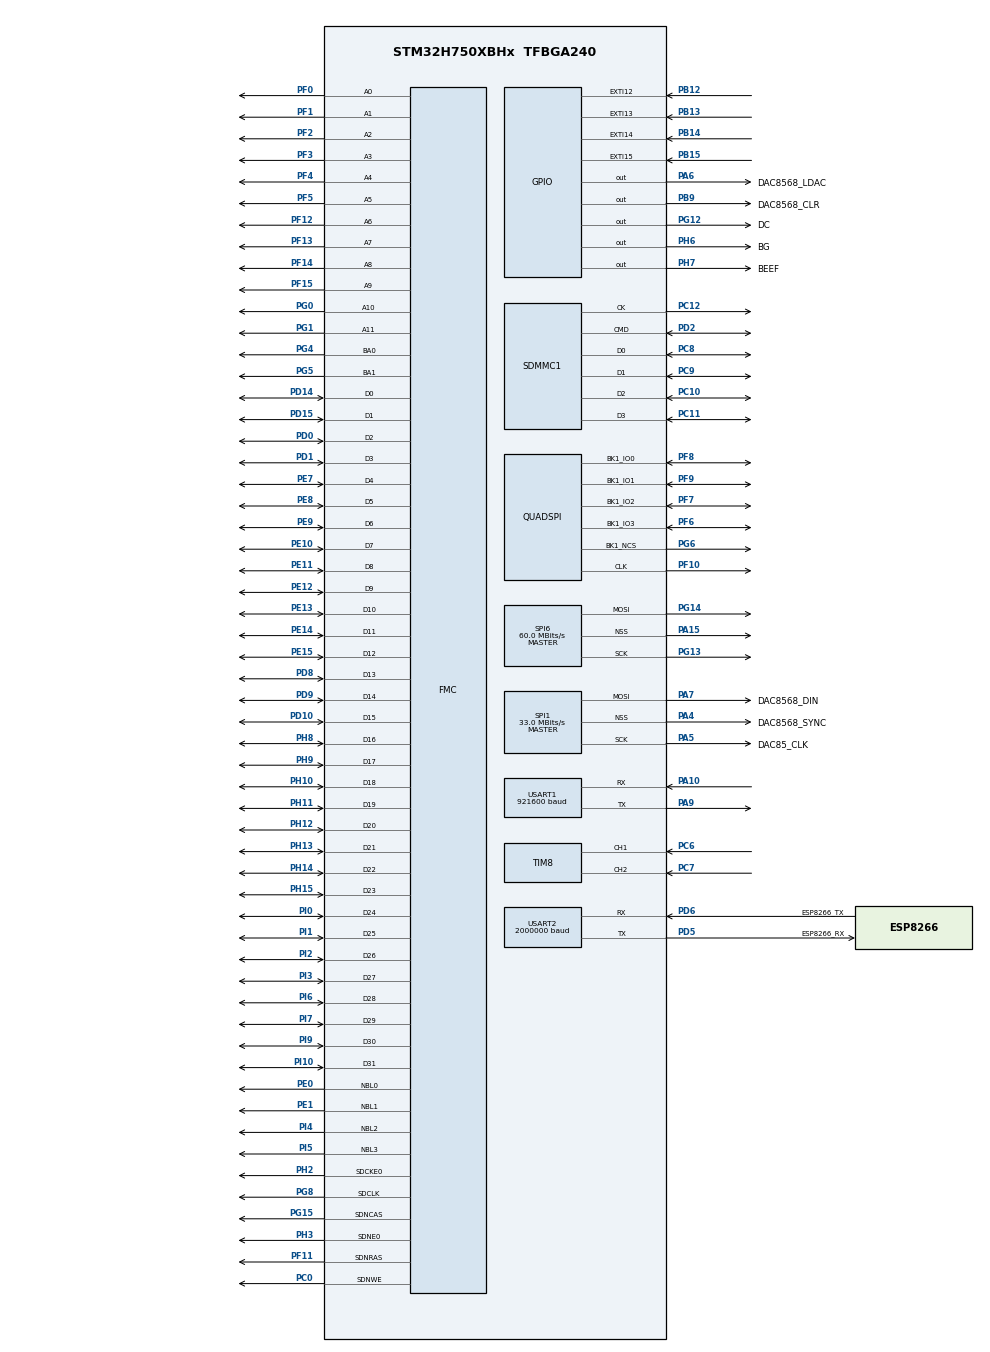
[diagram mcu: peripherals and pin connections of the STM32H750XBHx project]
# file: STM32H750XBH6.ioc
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CORTEX_M7.AccessPermission-Cortex_Memory_Protection_Unit_Region0_Settings=MPU_REGION_FULL_ACCESS
CORTEX_M7.AccessPermission-Cortex_Memory_Protection_Unit_Region1_Settings=MPU_REGION_FULL_ACCESS
CORTEX_M7.BaseAddress-Cortex_Memory_Protection_Unit_Region0_Settings=0xC0000000
CORTEX_M7.BaseAddress-Cortex_Memory_Protection_Unit_Region1_Settings=0x24000000
CORTEX_M7.CPU_DCache=Enabled
CORTEX_M7.CPU_ICache=Enabled
CORTEX_M7.Enable-Cortex_Memory_Protection_Unit_Region0_Settings=MPU_REGION_ENABLE
CORTEX_M7.Enable-Cortex_Memory_Protection_Unit_Region1_Settings=MPU_REGION_ENABLE
CORTEX_M7.IsBufferable-Cortex_Memory_Protection_Unit_Region0_Settings=MPU_ACCESS_NOT_BUFFERABLE
CORTEX_M7.IsBufferable-Cortex_Memory_Protection_Unit_Region1_Settings=MPU_ACCESS_BUFFERABLE
CORTEX_M7.IsCacheable-Cortex_Memory_Protection_Unit_Region0_Settings=MPU_ACCESS_CACHEABLE
CORTEX_M7.IsCacheable-Cortex_Memory_Protection_Unit_Region1_Settings=MPU_ACCESS_CACHEABLE
CORTEX_M7.IsShareable-Cortex_Memory_Protection_Unit_Region1_Settings=MPU_ACCESS_SHAREABLE
CORTEX_M7.MPU_Control=MPU_PRIVILEGED_DEFAULT
CORTEX_M7.Size-Cortex_Memory_Protection_Unit_Region0_Settings=MPU_REGION_SIZE_16MB
CORTEX_M7.Size-Cortex_Memory_Protection_Unit_Region1_Settings=MPU_REGION_SIZE_512KB
CORTEX_M7.TypeExtField-Cortex_Memory_Protection_Unit_Region1_Settings=MPU_TEX_LEVEL1
DMA2D.ColorMode=DMA2D_OUTPUT_RGB565
Dma.Request0=USART1_RX
Dma.Request1=USART1_TX
Dma.Request2=USART2_RX
Dma.Request3=USART2_TX
Dma.Request4=SPI1_TX
Dma.SPI1_TX.4.Direction=DMA_MEMORY_TO_PERIPH
Dma.SPI1_TX.4.EventEnable=DISABLE
Dma.SPI1_TX.4.FIFOMode=DMA_FIFOMODE_DISABLE
Dma.SPI1_TX.4.Instance=DMA1_Stream4
Dma.SPI1_TX.4.MemDataAlignment=DMA_MDATAALIGN_WORD
Dma.SPI1_TX.4.MemInc=DMA_MINC_ENABLE
Dma.SPI1_TX.4.Mode=DMA_CIRCULAR
Dma.SPI1_TX.4.PeriphDataAlignment=DMA_PDATAALIGN_WORD
Dma.SPI1_TX.4.PeriphInc=DMA_PINC_DISABLE
Dma.SPI1_TX.4.Polarity=HAL_DMAMUX_REQ_GEN_RISING
Dma.SPI1_TX.4.Priority=DMA_PRIORITY_HIGH
Dma.SPI1_TX.4.RequestNumber=1
Dma.SPI1_TX.4.SignalID=NONE
Dma.SPI1_TX.4.SyncEnable=DISABLE
Dma.SPI1_TX.4.SyncPolarity=HAL_DMAMUX_SYNC_NO_EVENT
Dma.SPI1_TX.4.SyncRequestNumber=1
Dma.SPI1_TX.4.SyncSignalID=NONE
Dma.USART1_RX.0.Direction=DMA_PERIPH_TO_MEMORY
Dma.USART1_RX.0.EventEnable=DISABLE
Dma.USART1_RX.0.FIFOMode=DMA_FIFOMODE_DISABLE
Dma.USART1_RX.0.Instance=DMA1_Stream0
Dma.USART1_RX.0.MemDataAlignment=DMA_MDATAALIGN_BYTE
Dma.USART1_RX.0.MemInc=DMA_MINC_ENABLE
Dma.USART1_RX.0.Mode=DMA_NORMAL
Dma.USART1_RX.0.PeriphDataAlignment=DMA_PDATAALIGN_BYTE
Dma.USART1_RX.0.PeriphInc=DMA_PINC_DISABLE
Dma.USART1_RX.0.Polarity=HAL_DMAMUX_REQ_GEN_RISING
Dma.USART1_RX.0.Priority=DMA_PRIORITY_VERY_HIGH
Dma.USART1_RX.0.RequestNumber=1
Dma.USART1_RX.0.SignalID=NONE
Dma.USART1_RX.0.SyncEnable=DISABLE
Dma.USART1_RX.0.SyncPolarity=HAL_DMAMUX_SYNC_NO_EVENT
Dma.USART1_RX.0.SyncRequestNumber=1
Dma.USART1_RX.0.SyncSignalID=NONE
Dma.USART1_TX.1.Direction=DMA_MEMORY_TO_PERIPH
Dma.USART1_TX.1.EventEnable=DISABLE
Dma.USART1_TX.1.FIFOMode=DMA_FIFOMODE_DISABLE
Dma.USART1_TX.1.Instance=DMA1_Stream1
Dma.USART1_TX.1.MemDataAlignment=DMA_MDATAALIGN_BYTE
Dma.USART1_TX.1.MemInc=DMA_MINC_ENABLE
Dma.USART1_TX.1.Mode=DMA_NORMAL
Dma.USART1_TX.1.PeriphDataAlignment=DMA_PDATAALIGN_BYTE
Dma.USART1_TX.1.PeriphInc=DMA_PINC_DISABLE
Dma.USART1_TX.1.Polarity=HAL_DMAMUX_REQ_GEN_RISING
Dma.USART1_TX.1.Priority=DMA_PRIORITY_VERY_HIGH
Dma.USART1_TX.1.RequestNumber=1
Dma.USART1_TX.1.SignalID=NONE
Dma.USART1_TX.1.SyncEnable=DISABLE
Dma.USART1_TX.1.SyncPolarity=HAL_DMAMUX_SYNC_NO_EVENT
Dma.USART1_TX.1.SyncRequestNumber=1
Dma.USART1_TX.1.SyncSignalID=NONE
Dma.USART2_RX.2.Direction=DMA_PERIPH_TO_MEMORY
Dma.USART2_RX.2.EventEnable=DISABLE
Dma.USART2_RX.2.FIFOMode=DMA_FIFOMODE_DISABLE
Dma.USART2_RX.2.Instance=DMA1_Stream2
Dma.USART2_RX.2.MemDataAlignment=DMA_MDATAALIGN_BYTE
Dma.USART2_RX.2.MemInc=DMA_MINC_ENABLE
Dma.USART2_RX.2.Mode=DMA_CIRCULAR
Dma.USART2_RX.2.PeriphDataAlignment=DMA_PDATAALIGN_BYTE
Dma.USART2_RX.2.PeriphInc=DMA_PINC_DISABLE
Dma.USART2_RX.2.Polarity=HAL_DMAMUX_REQ_GEN_RISING
Dma.USART2_RX.2.Priority=DMA_PRIORITY_VERY_HIGH
Dma.USART2_RX.2.RequestNumber=1
Dma.USART2_RX.2.SignalID=NONE
Dma.USART2_RX.2.SyncEnable=DISABLE
Dma.USART2_RX.2.SyncPolarity=HAL_DMAMUX_SYNC_NO_EVENT
Dma.USART2_RX.2.SyncRequestNumber=1
Dma.USART2_RX.2.SyncSignalID=NONE
Dma.USART2_TX.3.Direction=DMA_MEMORY_TO_PERIPH
Dma.USART2_TX.3.EventEnable=DISABLE
Dma.USART2_TX.3.FIFOMode=DMA_FIFOMODE_DISABLE
Dma.USART2_TX.3.Instance=DMA1_Stream3
Dma.USART2_TX.3.MemDataAlignment=DMA_MDATAALIGN_BYTE
Dma.USART2_TX.3.MemInc=DMA_MINC_ENABLE
Dma.USART2_TX.3.Mode=DMA_NORMAL
Dma.USART2_TX.3.PeriphDataAlignment=DMA_PDATAALIGN_BYTE
Dma.USART2_TX.3.PeriphInc=DMA_PINC_DISABLE
Dma.USART2_TX.3.Polarity=HAL_DMAMUX_REQ_GEN_RISING
Dma.USART2_TX.3.Priority=DMA_PRIORITY_VERY_HIGH
Dma.USART2_TX.3.RequestNumber=1
Dma.USART2_TX.3.SignalID=NONE
Dma.USART2_TX.3.SyncEnable=DISABLE
Dma.USART2_TX.3.SyncPolarity=HAL_DMAMUX_SYNC_NO_EVENT
Dma.USART2_TX.3.SyncRequestNumber=1
Dma.USART2_TX.3.SyncSignalID=NONE
FATFS._CODE_PAGE=437
FATFS._FS_LOCK=16
FATFS._USE_LFN=3
FATFS._VOLUMES=1
FMC.CASLatency1=FMC_SDRAM_CAS_LATENCY_3
FMC.ColumnBitsNumber1=FMC_SDRAM_COLUMN_BITS_NUM_8
FMC.ExitSelfRefreshDelay1=7
FMC.LoadToActiveDelay1=2
FMC.RCDDelay1=2
FMC.RPDelay1=2
FMC.RPDelay2=2
FMC.ReadBurst1=FMC_SDRAM_RBURST_ENABLE
FMC.ReadBurst2=FMC_SDRAM_RBURST_ENABLE
FMC.RowCycleDelay1=7
FMC.RowCycleDelay2=7
FMC.SDClockPeriod1=FMC_SDRAM_CLOCK_PERIOD_2
FMC.SDClockPeriod2=FMC_SDRAM_CLOCK_PERIOD_2
FMC.SelfRefreshTime1=4
FMC.WriteRecoveryTime1=3
FREERTOS.Tasks01=LVGL940,24,2048,LVGL_Task,Default,NULL,Dynamic,NULL,NULL;LED,8,128,LED_Task,Default,NULL,Dynamic,NULL,NULL;Main,8,8192,Main_Task,Default,NULL,Dynamic,NULL,NULL;ESP8266,32,5128,ESP8266_Task,Default,NULL,Dynamic,NULL,NULL
FREERTOS.configTOTAL_HEAP_SIZE=102400
FREERTOS.configUSE_TICK_HOOK=1
Mcu.Family=STM32H7
Mcu.Name=STM32H750XBHx
Mcu.Package=TFBGA240
Mdma.MDMA_Channel0.Request0=SDMMC1_END_DATA
Mdma.MDMA_Channel0.RequestsNb=1
Mdma.MDMA_Channel0.SDMMC1_END_DATA.0.BlockCount=0
Mdma.MDMA_Channel0.SDMMC1_END_DATA.0.BlockDataLength=0
Mdma.MDMA_Channel0.SDMMC1_END_DATA.0.BufferTransferLength=1
Mdma.MDMA_Channel0.SDMMC1_END_DATA.0.CircularMode=MDMA_LINEAR_LIST
Mdma.MDMA_Channel0.SDMMC1_END_DATA.0.DataAlignment=MDMA_DATAALIGN_PACKENABLE
Mdma.MDMA_Channel0.SDMMC1_END_DATA.0.DestBlockAddressOffset=0
Mdma.MDMA_Channel0.SDMMC1_END_DATA.0.DestBurst=MDMA_DEST_BURST_SINGLE
Mdma.MDMA_Channel0.SDMMC1_END_DATA.0.DestDataSize=MDMA_DEST_DATASIZE_BYTE
Mdma.MDMA_Channel0.SDMMC1_END_DATA.0.DestinationInc=MDMA_DEST_INC_BYTE
Mdma.MDMA_Channel0.SDMMC1_END_DATA.0.DstAddress=0
Mdma.MDMA_Channel0.SDMMC1_END_DATA.0.Endianness=MDMA_LITTLE_ENDIANNESS_PRESERVE
Mdma.MDMA_Channel0.SDMMC1_END_DATA.0.Instance=MDMA_Channel0
Mdma.MDMA_Channel0.SDMMC1_END_DATA.0.MaskAddress=0
Mdma.MDMA_Channel0.SDMMC1_END_DATA.0.MaskData=0
Mdma.MDMA_Channel0.SDMMC1_END_DATA.0.Priority=MDMA_PRIORITY_LOW
Mdma.MDMA_Channel0.SDMMC1_END_DATA.0.Rank=First
Mdma.MDMA_Channel0.SDMMC1_END_DATA.0.SourceBlockAddressOffset=0
Mdma.MDMA_Channel0.SDMMC1_END_DATA.0.SourceBurst=MDMA_SOURCE_BURST_SINGLE
Mdma.MDMA_Channel0.SDMMC1_END_DATA.0.SourceDataSize=MDMA_SRC_DATASIZE_BYTE
Mdma.MDMA_Channel0.SDMMC1_END_DATA.0.SourceInc=MDMA_SRC_INC_BYTE
Mdma.MDMA_Channel0.SDMMC1_END_DATA.0.SrcAddress=0
Mdma.MDMA_Channel0.SDMMC1_END_DATA.0.TransferTriggerMode=MDMA_BUFFER_TRANSFER
Mdma.MDMA_Channel1.QUADSPI_FIFO_TH.0.BlockCount=0
Mdma.MDMA_Channel1.QUADSPI_FIFO_TH.0.BlockDataLength=0
Mdma.MDMA_Channel1.QUADSPI_FIFO_TH.0.BufferTransferLength=128
Mdma.MDMA_Channel1.QUADSPI_FIFO_TH.0.CircularMode=MDMA_LINEAR_LIST
Mdma.MDMA_Channel1.QUADSPI_FIFO_TH.0.DataAlignment=MDMA_DATAALIGN_PACKENABLE
Mdma.MDMA_Channel1.QUADSPI_FIFO_TH.0.DestBlockAddressOffset=0
Mdma.MDMA_Channel1.QUADSPI_FIFO_TH.0.DestBurst=MDMA_DEST_BURST_SINGLE
Mdma.MDMA_Channel1.QUADSPI_FIFO_TH.0.DestDataSize=MDMA_DEST_DATASIZE_WORD
Mdma.MDMA_Channel1.QUADSPI_FIFO_TH.0.DestinationInc=MDMA_DEST_INC_DISABLE
Mdma.MDMA_Channel1.QUADSPI_FIFO_TH.0.DstAddress=0
Mdma.MDMA_Channel1.QUADSPI_FIFO_TH.0.Endianness=MDMA_LITTLE_ENDIANNESS_PRESERVE
Mdma.MDMA_Channel1.QUADSPI_FIFO_TH.0.Instance=MDMA_Channel1
Mdma.MDMA_Channel1.QUADSPI_FIFO_TH.0.MaskAddress=0
Mdma.MDMA_Channel1.QUADSPI_FIFO_TH.0.MaskData=0
Mdma.MDMA_Channel1.QUADSPI_FIFO_TH.0.Priority=MDMA_PRIORITY_VERY_HIGH
Mdma.MDMA_Channel1.QUADSPI_FIFO_TH.0.Rank=First
Mdma.MDMA_Channel1.QUADSPI_FIFO_TH.0.SourceBlockAddressOffset=0
Mdma.MDMA_Channel1.QUADSPI_FIFO_TH.0.SourceBurst=MDMA_SOURCE_BURST_SINGLE
Mdma.MDMA_Channel1.QUADSPI_FIFO_TH.0.SourceDataSize=MDMA_SRC_DATASIZE_WORD
Mdma.MDMA_Channel1.QUADSPI_FIFO_TH.0.SourceInc=MDMA_SRC_INC_WORD
Mdma.MDMA_Channel1.QUADSPI_FIFO_TH.0.SrcAddress=0
Mdma.MDMA_Channel1.QUADSPI_FIFO_TH.0.TransferTriggerMode=MDMA_BUFFER_TRANSFER
Mdma.MDMA_Channel1.Request0=QUADSPI_FIFO_TH
Mdma.MDMA_Channel1.RequestsNb=1
Mdma.RequestSet0=MDMA_Channel0
Mdma.RequestSet1=MDMA_Channel1
Mdma.RequestSetsNb=2
NVIC.DMA1_Stream0_IRQn=true\:5\:0\:false\:false\:true\:true\:false\:true\:true
NVIC.DMA1_Stream1_IRQn=true\:5\:0\:false\:false\:true\:true\:false\:true\:true
NVIC.DMA1_Stream2_IRQn=true\:5\:0\:false\:false\:true\:true\:false\:true\:true
NVIC.DMA1_Stream3_IRQn=true\:5\:0\:false\:false\:true\:true\:false\:true\:true
NVIC.DMA1_Stream4_IRQn=true\:5\:0\:false\:false\:true\:true\:false\:true\:true
NVIC.EXTI15_10_IRQn=true\:7\:0\:true\:false\:true\:true\:true\:true\:true
NVIC.MDMA_IRQn=true\:6\:0\:true\:false\:true\:true\:false\:true\:true
NVIC.PriorityGroup=NVIC_PRIORITYGROUP_4
NVIC.QUADSPI_IRQn=true\:5\:0\:false\:false\:true\:true\:true\:true\:true
NVIC.SDMMC1_IRQn=true\:6\:0\:true\:false\:true\:true\:true\:true\:true
NVIC.SPI1_IRQn=true\:5\:0\:false\:false\:true\:true\:false\:true\:true
NVIC.TIM17_IRQn=true\:15\:0\:false\:false\:true\:false\:false\:true\:true
NVIC.TIM3_IRQn=true\:5\:0\:false\:false\:true\:true\:true\:true\:true
NVIC.TIM8_BRK_TIM12_IRQn=true\:5\:0\:false\:false\:true\:true\:true\:true\:true
NVIC.TimeBase=TIM17_IRQn
NVIC.TimeBaseIP=TIM17
NVIC.USART1_IRQn=true\:5\:0\:false\:false\:true\:true\:true\:true\:true
NVIC.USART2_IRQn=true\:5\:0\:false\:false\:true\:true\:true\:true\:true
PA10.GPIO_Speed=GPIO_SPEED_FREQ_VERY_HIGH
PA10.Mode=Asynchronous
PA10.PinAttribute=Free
PA10.Signal=USART1_RX
PA13\ (JTMS/SWDIO).Mode=Serial_Wire
PA13\ (JTMS/SWDIO).Signal=DEBUG_JTMS-SWDIO
PA14\ (JTCK/SWCLK).Mode=Serial_Wire
PA14\ (JTCK/SWCLK).PinAttribute=Free
PA14\ (JTCK/SWCLK).Signal=DEBUG_JTCK-SWCLK
PA15\ (JTDI).GPIO_Speed=GPIO_SPEED_FREQ_VERY_HIGH
PA15\ (JTDI).Mode=NSS_Signal_Hard_Output
PA15\ (JTDI).Signal=SPI6_NSS
PA4.GPIO_Label=DAC8568_SYNC
PA4.GPIO_Speed=GPIO_SPEED_FREQ_VERY_HIGH
PA4.Mode=NSS_Signal_Hard_Output
PA4.Signal=SPI1_NSS
PA5.GPIO_Label=DAC85_CLK
PA5.GPIO_Speed=GPIO_SPEED_FREQ_LOW
PA5.Mode=TX_Only_Simplex_Unidirect_Master
PA5.PinAttribute=Free
PA5.Signal=SPI1_SCK
PA6.GPIO_Label=DAC8568_LDAC
PA6.GPIO_Speed=GPIO_SPEED_FREQ_VERY_HIGH
PA6.PinAttribute=Free
PA6.PinState=GPIO_PIN_SET
PA6.Signal=GPIO_Output
PA7.GPIO_Label=DAC8568_DIN
PA7.GPIO_Speed=GPIO_SPEED_FREQ_LOW
PA7.Mode=TX_Only_Simplex_Unidirect_Master
PA7.PinAttribute=Free
PA7.Signal=SPI1_MOSI
PA9.GPIO_Speed=GPIO_SPEED_FREQ_VERY_HIGH
PA9.Mode=Asynchronous
PA9.PinAttribute=Free
PA9.Signal=USART1_TX
PB12.GPIO_ModeDefaultEXTI=GPIO_MODE_IT_FALLING
PB12.GPIO_PuPd=GPIO_PULLUP
PB12.PinAttribute=Free
PB12.Signal=GPXTI12
PB13.GPIO_ModeDefaultEXTI=GPIO_MODE_IT_FALLING
PB13.GPIO_PuPd=GPIO_PULLUP
PB13.Signal=GPXTI13
PB14.GPIO_ModeDefaultEXTI=GPIO_MODE_IT_FALLING
PB14.GPIO_PuPd=GPIO_PULLUP
PB14.Signal=GPXTI14
PB15.GPIO_ModeDefaultEXTI=GPIO_MODE_IT_FALLING
PB15.GPIO_PuPd=GPIO_PULLUP
PB15.PinAttribute=Free
PB15.Signal=GPXTI15
PB9.GPIO_Label=DAC8568_CLR
PB9.GPIO_Speed=GPIO_SPEED_FREQ_LOW
PB9.PinState=GPIO_PIN_SET
PB9.Signal=GPIO_Output
PC0.Signal=FMC_SDNWE
PC10.GPIO_PuPd=GPIO_NOPULL
PC10.Mode=SD_4_bits_Wide_bus
PC10.Signal=SDMMC1_D2
PC11.GPIO_PuPd=GPIO_NOPULL
PC11.Mode=SD_4_bits_Wide_bus
PC11.PinAttribute=Free
PC11.Signal=SDMMC1_D3
PC12.GPIO_PuPd=GPIO_NOPULL
PC12.Mode=SD_4_bits_Wide_bus
PC12.Signal=SDMMC1_CK
PC14-OSC32_IN\ (OSC32_IN).Mode=LSE-External-Oscillator
PC14-OSC32_IN\ (OSC32_IN).Signal=RCC_OSC32_IN
PC15-OSC32_OUT\ (OSC32_OUT).Mode=LSE-External-Oscillator
PC15-OSC32_OUT\ (OSC32_OUT).Signal=RCC_OSC32_OUT
PC6.Signal=S_TIM8_CH1
PC7.Signal=S_TIM8_CH2
PC8.GPIO_PuPd=GPIO_NOPULL
PC8.Mode=SD_4_bits_Wide_bus
PC8.PinAttribute=Free
PC8.Signal=SDMMC1_D0
PC9.GPIO_PuPd=GPIO_NOPULL
PC9.Mode=SD_4_bits_Wide_bus
PC9.PinAttribute=Free
PC9.Signal=SDMMC1_D1
PD0.PinAttribute=Free
PD0.Signal=FMC_D2_DA2
PD1.PinAttribute=Free
PD1.Signal=FMC_D3_DA3
PD10.Signal=FMC_D15_DA15
PD14.Signal=FMC_D0_DA0
PD15.Signal=FMC_D1_DA1
PD2.GPIO_PuPd=GPIO_NOPULL
PD2.Mode=SD_4_bits_Wide_bus
PD2.PinAttribute=Free
PD2.Signal=SDMMC1_CMD
PD5.GPIO_Label=ESP8266_RX
PD5.GPIO_Speed=GPIO_SPEED_FREQ_VERY_HIGH
PD5.Mode=Asynchronous
PD5.Signal=USART2_TX
PD6.GPIO_Label=ESP8266_TX
PD6.GPIO_Speed=GPIO_SPEED_FREQ_VERY_HIGH
PD6.Mode=Asynchronous
PD6.PinAttribute=Free
PD6.Signal=USART2_RX
PD8.Signal=FMC_D13_DA13
PD9.Signal=FMC_D14_DA14
PE0.Signal=FMC_NBL0
PE1.Signal=FMC_NBL1
PE10.Signal=FMC_D7_DA7
PE11.Signal=FMC_D8_DA8
PE12.PinAttribute=Free
PE12.Signal=FMC_D9_DA9
PE13.PinAttribute=Free
PE13.Signal=FMC_D10_DA10
PE14.Signal=FMC_D11_DA11
PE15.PinAttribute=Free
PE15.Signal=FMC_D12_DA12
PE7.Signal=FMC_D4_DA4
PE8.PinAttribute=Free
PE8.Signal=FMC_D5_DA5
PE9.Signal=FMC_D6_DA6
PF0.Signal=FMC_A0
PF1.Signal=FMC_A1
PF10.GPIO_Speed=GPIO_SPEED_FREQ_VERY_HIGH
PF10.Mode=Single Bank 1
PF10.Signal=QUADSPI_CLK
PF11.PinAttribute=Free
PF11.Signal=FMC_SDNRAS
PF12.PinAttribute=Free
PF12.Signal=FMC_A6
PF13.Signal=FMC_A7
PF14.Signal=FMC_A8
PF15.PinAttribute=Free
PF15.Signal=FMC_A9
PF2.Signal=FMC_A2
PF3.Signal=FMC_A3
PF4.Signal=FMC_A4
PF5.Signal=FMC_A5
PF6.GPIO_Speed=GPIO_SPEED_FREQ_VERY_HIGH
PF6.Mode=Single Bank 1
PF6.Signal=QUADSPI_BK1_IO3
PF7.GPIO_Speed=GPIO_SPEED_FREQ_VERY_HIGH
PF7.Mode=Single Bank 1
PF7.Signal=QUADSPI_BK1_IO2
PF8.GPIO_Speed=GPIO_SPEED_FREQ_VERY_HIGH
PF8.Mode=Single Bank 1
PF8.Signal=QUADSPI_BK1_IO0
PF9.GPIO_Speed=GPIO_SPEED_FREQ_VERY_HIGH
PF9.Mode=Single Bank 1
PF9.Signal=QUADSPI_BK1_IO1
PG0.PinAttribute=Free
PG0.Signal=FMC_A10
PG1.Signal=FMC_A11
PG12.GPIO_Label=DC
PG12.GPIO_Speed=GPIO_SPEED_FREQ_VERY_HIGH
PG12.Signal=GPIO_Output
PG13.GPIO_Speed=GPIO_SPEED_FREQ_VERY_HIGH
PG13.Mode=TX_Only_Simplex_Unidirect_Master
PG13.PinAttribute=Free
PG13.Signal=SPI6_SCK
PG14.GPIO_Speed=GPIO_SPEED_FREQ_VERY_HIGH
PG14.Mode=TX_Only_Simplex_Unidirect_Master
PG14.Signal=SPI6_MOSI
PG15.Signal=FMC_SDNCAS
PG4.Signal=FMC_A14_BA0
PG5.Signal=FMC_A15_BA1
PG6.GPIO_Speed=GPIO_SPEED_FREQ_VERY_HIGH
PG6.Mode=Single Bank 1
PG6.Signal=QUADSPI_BK1_NCS
PG8.Signal=FMC_SDCLK
PH0-OSC_IN\ (PH0).Mode=HSE-External-Oscillator
PH0-OSC_IN\ (PH0).Signal=RCC_OSC_IN
PH1-OSC_OUT\ (PH1).Mode=HSE-External-Oscillator
PH1-OSC_OUT\ (PH1).Signal=RCC_OSC_OUT
PH10.Signal=FMC_D18
PH11.Signal=FMC_D19
PH12.PinAttribute=Free
PH12.Signal=FMC_D20
PH13.PinAttribute=Free
PH13.Signal=FMC_D21
PH14.Signal=FMC_D22
PH15.Signal=FMC_D23
PH2.Mode=SdramChipSelect1_1
PH2.Signal=FMC_SDCKE0
PH3.Mode=SdramChipSelect1_1
PH3.Signal=FMC_SDNE0
PH6.GPIO_Label=BG
PH6.GPIO_Speed=GPIO_SPEED_FREQ_VERY_HIGH
PH6.PinAttribute=Free
PH6.PinState=GPIO_PIN_SET
PH6.Signal=GPIO_Output
PH7.GPIO_Label=BEEF
PH7.GPIO_Speed=GPIO_SPEED_FREQ_VERY_HIGH
PH7.PinState=GPIO_PIN_SET
PH7.Signal=GPIO_Output
PH8.PinAttribute=Free
PH8.Signal=FMC_D16
PH9.PinAttribute=Free
PH9.Signal=FMC_D17
PI0.Signal=FMC_D24
PI1.Signal=FMC_D25
PI10.Signal=FMC_D31
PI2.Signal=FMC_D26
PI3.Signal=FMC_D27
PI4.Signal=FMC_NBL2
PI5.PinAttribute=Free
PI5.Signal=FMC_NBL3
PI6.Signal=FMC_D28
PI7.Signal=FMC_D29
PI9.PinAttribute=Free
PI9.Signal=FMC_D30
ProjectManager.HeapSize=0x2000
ProjectManager.StackSize=0x2000
ProjectManager.TargetToolchain=MDK-ARM V5.32
QUADSPI.ClockMode=QSPI_CLOCK_MODE_3
QUADSPI.ClockPrescaler=1
QUADSPI.FifoThreshold=32
QUADSPI.FlashSize=24
QUADSPI.SampleShifting=QSPI_SAMPLE_SHIFTING_HALFCYCLE
RCC.ADCFreq_Value=132000000
RCC.APB1Freq_Value=120000000
RCC.APB2Freq_Value=120000000
RCC.APB3Freq_Value=120000000
RCC.APB4Freq_Value=120000000
RCC.CortexFreq_Value=480000000
RCC.D1PPRE=RCC_APB3_DIV2
RCC.D2PPRE1=RCC_APB1_DIV2
RCC.D2PPRE2=RCC_APB2_DIV2
RCC.D3PPRE=RCC_APB4_DIV2
RCC.DIVM1=4
RCC.DIVM3=8
RCC.DIVN1=60
RCC.DIVN2=132
RCC.DIVN3=50
RCC.DIVQ1=4
RCC.DIVQ3=8
RCC.DIVR3=8
RCC.HCLKFreq_Value=240000000
RCC.HPRE=RCC_HCLK_DIV2
RCC.PLL2FRACN=0
RCC.PLL3FRACN=0
RCC.PLLFRACN=0
RCC.RTCClockSelection=RCC_RTCCLKSOURCE_LSE
RCC.SPI123CLockSelection=RCC_SPI123CLKSOURCE_PLL2
RCC.SYSCLKFreq_VALUE=480000000
RCC.SYSCLKSource=RCC_SYSCLKSOURCE_PLLCLK
RCC.USBFreq_Value=240000000
SDMMC1.ClockDiv=0
SH.FMC_A0.0=FMC_A0,12b-sda1
SH.FMC_A1.0=FMC_A1,12b-sda1
SH.FMC_A10.0=FMC_A10,12b-sda1
SH.FMC_A11.0=FMC_A11,12b-sda1
SH.FMC_A14_BA0.0=FMC_BA0,FourSdramBanks1
SH.FMC_A15_BA1.0=FMC_BA1,FourSdramBanks1
SH.FMC_A2.0=FMC_A2,12b-sda1
SH.FMC_A3.0=FMC_A3,12b-sda1
SH.FMC_A4.0=FMC_A4,12b-sda1
SH.FMC_A5.0=FMC_A5,12b-sda1
SH.FMC_A6.0=FMC_A6,12b-sda1
SH.FMC_A7.0=FMC_A7,12b-sda1
SH.FMC_A8.0=FMC_A8,12b-sda1
SH.FMC_A9.0=FMC_A9,12b-sda1
SH.FMC_D0_DA0.0=FMC_D0,sd-32b-d1
SH.FMC_D10_DA10.0=FMC_D10,sd-32b-d1
SH.FMC_D11_DA11.0=FMC_D11,sd-32b-d1
SH.FMC_D12_DA12.0=FMC_D12,sd-32b-d1
SH.FMC_D13_DA13.0=FMC_D13,sd-32b-d1
SH.FMC_D14_DA14.0=FMC_D14,sd-32b-d1
SH.FMC_D15_DA15.0=FMC_D15,sd-32b-d1
SH.FMC_D16.0=FMC_D16,sd-32b-d1
SH.FMC_D17.0=FMC_D17,sd-32b-d1
SH.FMC_D18.0=FMC_D18,sd-32b-d1
SH.FMC_D19.0=FMC_D19,sd-32b-d1
SH.FMC_D1_DA1.0=FMC_D1,sd-32b-d1
SH.FMC_D20.0=FMC_D20,sd-32b-d1
SH.FMC_D21.0=FMC_D21,sd-32b-d1
SH.FMC_D22.0=FMC_D22,sd-32b-d1
SH.FMC_D23.0=FMC_D23,sd-32b-d1
SH.FMC_D24.0=FMC_D24,sd-32b-d1
SH.FMC_D25.0=FMC_D25,sd-32b-d1
SH.FMC_D26.0=FMC_D26,sd-32b-d1
SH.FMC_D27.0=FMC_D27,sd-32b-d1
SH.FMC_D28.0=FMC_D28,sd-32b-d1
SH.FMC_D29.0=FMC_D29,sd-32b-d1
SH.FMC_D2_DA2.0=FMC_D2,sd-32b-d1
SH.FMC_D30.0=FMC_D30,sd-32b-d1
SH.FMC_D31.0=FMC_D31,sd-32b-d1
SH.FMC_D3_DA3.0=FMC_D3,sd-32b-d1
SH.FMC_D4_DA4.0=FMC_D4,sd-32b-d1
SH.FMC_D5_DA5.0=FMC_D5,sd-32b-d1
SH.FMC_D6_DA6.0=FMC_D6,sd-32b-d1
SH.FMC_D7_DA7.0=FMC_D7,sd-32b-d1
SH.FMC_D8_DA8.0=FMC_D8,sd-32b-d1
SH.FMC_D9_DA9.0=FMC_D9,sd-32b-d1
SH.FMC_NBL0.0=FMC_NBL0,Sd4ByteEnable1
SH.FMC_NBL1.0=FMC_NBL1,Sd4ByteEnable1
SH.FMC_NBL2.0=FMC_NBL2,Sd4ByteEnable1
SH.FMC_NBL3.0=FMC_NBL3,Sd4ByteEnable1
SH.FMC_SDCLK.0=FMC_SDCLK,12b-sda1
SH.FMC_SDNCAS.0=FMC_SDNCAS,12b-sda1
SH.FMC_SDNRAS.0=FMC_SDNRAS,12b-sda1
SH.FMC_SDNWE.0=FMC_SDNWE,12b-sda1
SH.S_TIM8_CH1.0=TIM8_CH1,Encoder_Interface
SH.S_TIM8_CH2.0=TIM8_CH2,Encoder_Interface
SPI1.BaudRatePrescaler=SPI_BAUDRATEPRESCALER_4
SPI1.CLKPhase=SPI_PHASE_2EDGE
SPI1.CalculateBaudRate=33.0 MBits/s
SPI1.DataSize=SPI_DATASIZE_32BIT
SPI1.Direction=SPI_DIRECTION_2LINES_TXONLY
SPI1.MasterInterDataIdleness=SPI_MASTER_INTERDATA_IDLENESS_02CYCLE
SPI1.MasterSSIdleness=SPI_MASTER_SS_IDLENESS_02CYCLE
SPI1.Mode=SPI_MODE_MASTER
SPI1.VirtualNSS=VM_NSSHARD
SPI1.VirtualType=VM_MASTER
SPI6.CalculateBaudRate=60.0 MBits/s
SPI6.DataSize=SPI_DATASIZE_8BIT
SPI6.Direction=SPI_DIRECTION_2LINES_TXONLY
SPI6.FifoThreshold=SPI_FIFO_THRESHOLD_02DATA
SPI6.Mode=SPI_MODE_MASTER
SPI6.VirtualNSS=VM_NSSHARD
SPI6.VirtualType=VM_MASTER
TIM12.Period=1000-1
TIM12.TIM_MasterOutputTrigger=TIM_TRGO_UPDATE
TIM16.Prescaler=240-1
TIM3.Period=10000-1
TIM3.Prescaler=24000-1
TIM8.IC1Filter=0xF
USART1.BaudRate=921600
USART1.VirtualMode-Asynchronous=VM_ASYNC
USART2.BaudRate=2000000
USART2.FIFOMode=FIFOMODE_ENABLE
USART2.RXFIFOThreshold=RXFIFO_THRESHOLD_HALFFULL
USART2.VirtualMode-Asynchronous=VM_ASYNC
VP_DMA2D_VS_DMA2D.Mode=DMA2D_Activate
VP_FATFS_VS_SDIO.Mode=SDIO
VP_FREERTOS_VS_CMSIS_V2.Mode=CMSIS_V2
VP_MEMORYMAP_VS_MEMORYMAP.Mode=CurAppReg
VP_RTC_VS_RTC_Activate.Mode=RTC_Enabled
VP_RTC_VS_RTC_Calendar.Mode=RTC_Calendar
VP_SYS_VS_tim17.Mode=TIM17
VP_TIM12_VS_ClockSourceINT.Mode=Internal
VP_TIM16_VS_ClockSourceINT.Mode=Enable_Timer
VP_TIM3_VS_ClockSourceINT.Mode=Internal
board=custom

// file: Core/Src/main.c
/* USER CODE BEGIN Header */
/**
 ******************************************************************************
 * @file           : main.c
 * @brief          : Main program body
 ******************************************************************************
 * @attention
 *
 * Copyright (c) 2024 STMicroelectronics.
 * All rights reserved.
 *
 * This software is licensed under terms that can be found in the LICENSE file
 * in the root directory of this software component.
 * If no LICENSE file comes with this software, it is provided AS-IS.
 *
 ******************************************************************************
 */
/* USER CODE END Header */
#include "main.h"
#include "cmsis_os.h"
#include "dma.h"
#include "dma2d.h"
#include "fatfs.h"
#include "mdma.h"
#include "quadspi.h"
#include "rtc.h"
#include "sdmmc.h"
#include "spi.h"
#include "tim.h"
#include "usart.h"
#include "gpio.h"
#include "fmc.h"

/* USER CODE BEGIN Includes */
#include "led.h"
#include "sdram.h"
#include "lcd_spi_200.h"
#include "DAC8568/dac8568_dma.h"
#include "sd_waveform.h"
#include "lvgl.h"
#include "lv_port_disp.h"
#include "lv_port_indev.h"
// Demo 已移除，使用自定义 EdgeWind UI

#include <string.h>
#include "arm_math.h"
#include <stdio.h>
#include <stdarg.h>
#include "arm_const_structs.h"

#include <stdio.h>

/* USER CODE END Includes */

/* USER CODE BEGIN PV */
osMutexId_t mutex_id; //

const osMutexAttr_t Thread_Mutex_attr = {
    //
    "myThreadMutex",    // human readable mutex name     //
    osMutexPrioInherit, // attr_bits                 //
    NULL,               // memory for control block       //
    0U                  // size for control block        //
};

/* USER CODE END PV */

void SystemClock_Config(void);
static void MPU_Config(void);
void MX_FREERTOS_Init(void);

int main(void)
{

  /* MPU Configuration--------------------------------------------------------*/
  MPU_Config();

  /* Enable the CPU Cache */

  /* Enable I-Cache---------------------------------------------------------*/
  SCB_EnableICache();

  /* Enable D-Cache---------------------------------------------------------*/
  SCB_EnableDCache();

  /* MCU Configuration--------------------------------------------------------*/

  /* Reset of all peripherals, Initializes the Flash interface and the Systick. */
  HAL_Init();

  /* Configure the system clock */
  SystemClock_Config();

  /* Initialize all configured peripherals */
  MX_GPIO_Init();
  MX_MDMA_Init();
  MX_DMA_Init();
  MX_USART1_UART_Init();
  MX_FMC_Init();
  MX_DMA2D_Init();
  MX_TIM3_Init();
  MX_SDMMC1_SD_Init();
  MX_FATFS_Init();
  MX_RTC_Init();
  MX_TIM16_Init();
  MX_USART2_UART_Init();
  MX_QUADSPI_Init();
  MX_SPI1_Init();
  MX_TIM12_Init();
  MX_SPI6_Init();
  MX_TIM8_Init();
  /* USER CODE BEGIN 2 */
  //		Stack_Size      EQU     0x00000400 //
  //		Stack_Size      EQU     0x0000FF00

  /*
   * Fix DAC output spikes during UI key/page switching:
   *
   * - FreeRTOS masks interrupts at and below configLIBRARY_MAX_SYSCALL_INTERRUPT_PRIORITY (5)
   *   when entering critical sections (BASEPRI). CubeMX currently configures SPI1 TX DMA
   *   (DMA1_Stream4_IRQn) at priority 5, so it can be delayed long enough to miss the
   *   circular DMA refill window, producing waveform glitches.
   * - Raise the DAC streaming DMA IRQ priority above 5 (numerically smaller) so it is not
   *   masked by RTOS critical sections. Keep UI EXTI keys at a lower priority.
   *
   * NOTE: For long-term maintainability, mirror these priorities in CubeMX (NVIC tab).
   */
  HAL_NVIC_SetPriority(DMA1_Stream4_IRQn, 4, 0);
  HAL_NVIC_SetPriority(SPI1_IRQn, 4, 0);
  HAL_NVIC_SetPriority(EXTI15_10_IRQn, 7, 0);

  LED_Init();                              //
  SDRAM_Initialization_Sequence(&hsdram1); //
  /* SPI LCD init path (match d1f119 LCD display chain) */
  SPI_LCD_Init();
  LCD_SetBackColor(LCD_BLACK);
  LCD_Clear();
  LCD_SetColor(LCD_GREEN);
  LCD_SetAsciiFont(&ASCII_Font24);
  LCD_DisplayString(8, 8, "SPI LCD BOOT");

  /* Keep LTDC disabled to avoid RGB pipeline interference. */
  HAL_NVIC_DisableIRQ(LTDC_IRQn);
  __HAL_RCC_LTDC_CLK_DISABLE();

  /* DAC8568 streaming output (SPI1+DMA paced by TIM12 TRGO).
   * Wave sync + stream start is done in RTOS (see freertos.c Main_Task). */
  DAC8568_DMA_Init(DAC_SAMPLE_RATE_HZ);
  DAC8568_OutputFixedVoltage(0.0f);
  printf("[DAC] init ok, waiting SD sync in RTOS\r\n");

  printf("System Start...\r\n");

  //  FreeRTOS
  /* USER CODE END 2 */

  /* Init scheduler */
  osKernelInitialize();  /* Call init function for freertos objects (in cmsis_os2.c) */
  MX_FREERTOS_Init();

  /* Start scheduler */
  osKernelStart();

  /* We should never get here as control is now taken by the scheduler */

  /* Infinite loop */
  while (1)
  {

  }
}

void SystemClock_Config(void)
{
  RCC_OscInitTypeDef RCC_OscInitStruct = {0};
  RCC_ClkInitTypeDef RCC_ClkInitStruct = {0};

  /** Supply configuration update enable
  */
  HAL_PWREx_ConfigSupply(PWR_LDO_SUPPLY);

  /** Configure the main internal regulator output voltage
  */
  __HAL_PWR_VOLTAGESCALING_CONFIG(PWR_REGULATOR_VOLTAGE_SCALE0);

  while(!__HAL_PWR_GET_FLAG(PWR_FLAG_VOSRDY)) {}

  /** Configure LSE Drive Capability
  */
  HAL_PWR_EnableBkUpAccess();
  __HAL_RCC_LSEDRIVE_CONFIG(RCC_LSEDRIVE_LOW);

  /** Initializes the RCC Oscillators according to the specified parameters
  * in the RCC_OscInitTypeDef structure.
  */
  RCC_OscInitStruct.OscillatorType = RCC_OSCILLATORTYPE_HSI|RCC_OSCILLATORTYPE_LSE;
  RCC_OscInitStruct.LSEState = RCC_LSE_ON;
  RCC_OscInitStruct.HSIState = RCC_HSI_DIV1;
  RCC_OscInitStruct.HSICalibrationValue = RCC_HSICALIBRATION_DEFAULT;
  RCC_OscInitStruct.PLL.PLLState = RCC_PLL_ON;
  RCC_OscInitStruct.PLL.PLLSource = RCC_PLLSOURCE_HSI;
  RCC_OscInitStruct.PLL.PLLM = 4;
  RCC_OscInitStruct.PLL.PLLN = 60;
  RCC_OscInitStruct.PLL.PLLP = 2;
  RCC_OscInitStruct.PLL.PLLQ = 4;
  RCC_OscInitStruct.PLL.PLLR = 2;
  RCC_OscInitStruct.PLL.PLLRGE = RCC_PLL1VCIRANGE_3;
  RCC_OscInitStruct.PLL.PLLVCOSEL = RCC_PLL1VCOWIDE;
  RCC_OscInitStruct.PLL.PLLFRACN = 0;
  if (HAL_RCC_OscConfig(&RCC_OscInitStruct) != HAL_OK)
  {
    Error_Handler();
  }

  /** Initializes the CPU, AHB and APB buses clocks
  */
  RCC_ClkInitStruct.ClockType = RCC_CLOCKTYPE_HCLK|RCC_CLOCKTYPE_SYSCLK
                              |RCC_CLOCKTYPE_PCLK1|RCC_CLOCKTYPE_PCLK2
                              |RCC_CLOCKTYPE_D3PCLK1|RCC_CLOCKTYPE_D1PCLK1;
  RCC_ClkInitStruct.SYSCLKSource = RCC_SYSCLKSOURCE_PLLCLK;
  RCC_ClkInitStruct.SYSCLKDivider = RCC_SYSCLK_DIV1;
  RCC_ClkInitStruct.AHBCLKDivider = RCC_HCLK_DIV2;
  RCC_ClkInitStruct.APB3CLKDivider = RCC_APB3_DIV2;
  RCC_ClkInitStruct.APB1CLKDivider = RCC_APB1_DIV2;
  RCC_ClkInitStruct.APB2CLKDivider = RCC_APB2_DIV2;
  RCC_ClkInitStruct.APB4CLKDivider = RCC_APB4_DIV2;

  if (HAL_RCC_ClockConfig(&RCC_ClkInitStruct, FLASH_LATENCY_4) != HAL_OK)
  {
    Error_Handler();
  }
}

 /* MPU Configuration */

void MPU_Config(void)
{
  MPU_Region_InitTypeDef MPU_InitStruct = {0};

  /* Disables the MPU */
  HAL_MPU_Disable();

  /** Initializes and configures the Region and the memory to be protected
  */
  MPU_InitStruct.Enable = MPU_REGION_ENABLE;
  MPU_InitStruct.Number = MPU_REGION_NUMBER0;
  MPU_InitStruct.BaseAddress = 0xC0000000;
  MPU_InitStruct.Size = MPU_REGION_SIZE_16MB;
  MPU_InitStruct.SubRegionDisable = 0x0;
  MPU_InitStruct.TypeExtField = MPU_TEX_LEVEL0;
  MPU_InitStruct.AccessPermission = MPU_REGION_FULL_ACCESS;
  MPU_InitStruct.DisableExec = MPU_INSTRUCTION_ACCESS_ENABLE;
  MPU_InitStruct.IsShareable = MPU_ACCESS_NOT_SHAREABLE;
  MPU_InitStruct.IsCacheable = MPU_ACCESS_CACHEABLE;
  MPU_InitStruct.IsBufferable = MPU_ACCESS_NOT_BUFFERABLE;

  HAL_MPU_ConfigRegion(&MPU_InitStruct);

  /** Initializes and configures the Region and the memory to be protected
  */
  MPU_InitStruct.Number = MPU_REGION_NUMBER1;
  MPU_InitStruct.BaseAddress = 0x24000000;
  MPU_InitStruct.Size = MPU_REGION_SIZE_512KB;
  MPU_InitStruct.TypeExtField = MPU_TEX_LEVEL1;
  MPU_InitStruct.IsShareable = MPU_ACCESS_SHAREABLE;
  MPU_InitStruct.IsBufferable = MPU_ACCESS_BUFFERABLE;

  HAL_MPU_ConfigRegion(&MPU_InitStruct);
  /* Enables the MPU */
  HAL_MPU_Enable(MPU_PRIVILEGED_DEFAULT);

}

void HAL_TIM_PeriodElapsedCallback(TIM_HandleTypeDef *htim)
{
  if (htim->Instance == TIM17)
  {
    HAL_IncTick();
  }
  /* USER CODE BEGIN Callback 1 */
	if(htim->Instance == TIM3)  //
    {

    }
  if (htim->Instance == TIM2)
  {
    /* TIM2 保留，AD7606 采集逻辑已移除 */
  }
  /* USER CODE END Callback 1 */
}

void Error_Handler(void)
{
  __disable_irq();
  while (1)
  {
  }
}
